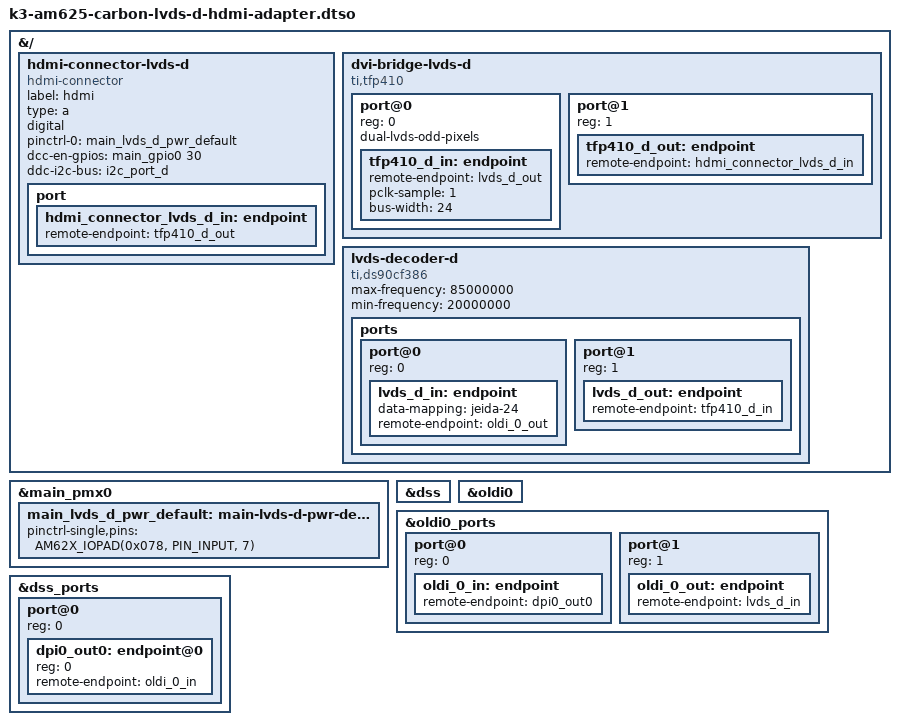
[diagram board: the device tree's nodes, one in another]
// SPDX-License-Identifier: GPL-2.0-only OR MIT
/*
 * LVDS D to HDMI Expansion Board for Carbon AM62xx
 *
 * Copyright (C) 2024 Ezurio LLC
 */

/dts-v1/;
/plugin/;

#include <dt-bindings/gpio/gpio.h>
#include "ti/k3-pinctrl.h"

&{/} {
	hdmi-connector-lvds-d {
		compatible = "hdmi-connector";
		label = "hdmi";
		type = "a";
		digital;

		pinctrl-names = "default";
		pinctrl-0 = <&main_lvds_d_pwr_default>;
		dcc-en-gpios = <&main_gpio0 30 GPIO_ACTIVE_HIGH>;

		ddc-i2c-bus = <&i2c_port_d>;

		/* Reenable after U3 VDD_5V miswiring fixed */
		//hpd-gpios = <&exp2 11 GPIO_ACTIVE_HIGH>;

		port {
			hdmi_connector_lvds_d_in: endpoint {
				remote-endpoint = <&tfp410_d_out>;
			};
		};
	};

	dvi-bridge-lvds-d {
		#address-cells = <1>;
		#size-cells = <0>;
		compatible = "ti,tfp410";

		port@0 {
			reg = <0>;
			dual-lvds-odd-pixels;
			tfp410_d_in: endpoint {
				remote-endpoint = <&lvds_d_out>;
				pclk-sample = <1>;
				bus-width = <24>;
			};
		};

		port@1 {
			reg = <1>;
			tfp410_d_out: endpoint {
				remote-endpoint = <&hdmi_connector_lvds_d_in>;
			};
		};
	};

	lvds-decoder-d {
		compatible = "ti,ds90cf386", "lvds-decoder";

		max-frequency = <85000000>;
		min-frequency = <20000000>;

		ports {
			#address-cells = <1>;
			#size-cells = <0>;

			port@0 {
				reg = <0>;
				lvds_d_in: endpoint {
					data-mapping = "jeida-24";
					remote-endpoint = <&oldi_0_out>;
				};
			};

			port@1 {
				reg = <1>;
				lvds_d_out: endpoint {
					remote-endpoint = <&tfp410_d_in>;
				};
			};
		};
	};
};

&main_pmx0 {
	main_lvds_d_pwr_default: main-lvds-d-pwr-default-pins {
		pinctrl-single,pins = <
			AM62X_IOPAD(0x078, PIN_INPUT, 7) /* LVDS_D_VDD_EN (U24) GPMC0_AD15.GPIO0_30 */
		>;
	};
};

&dss {
	status = "okay";
	/* OLDITX ports have no mux on them */
};

&oldi0 {
	status = "okay";
};

&oldi0_ports {
	#address-cells = <1>;
	#size-cells = <0>;

	port@0 {
		reg = <0>;
		oldi_0_in: endpoint {
			remote-endpoint = <&dpi0_out0>;
		};
	};

	port@1 {
		reg = <1>;
		oldi_0_out: endpoint {
			remote-endpoint = <&lvds_d_in>;
		};
	};
};

&dss_ports {
	#address-cells = <1>;
	#size-cells = <0>;

	/* Video Port 1 Output to OLDI */
	port@0 {
		reg = <0>;
		#address-cells = <1>;
		#size-cells = <0>;

		dpi0_out0: endpoint@0 {
			reg = <0>;
			remote-endpoint = <&oldi_0_in>;
		};
	};
};
